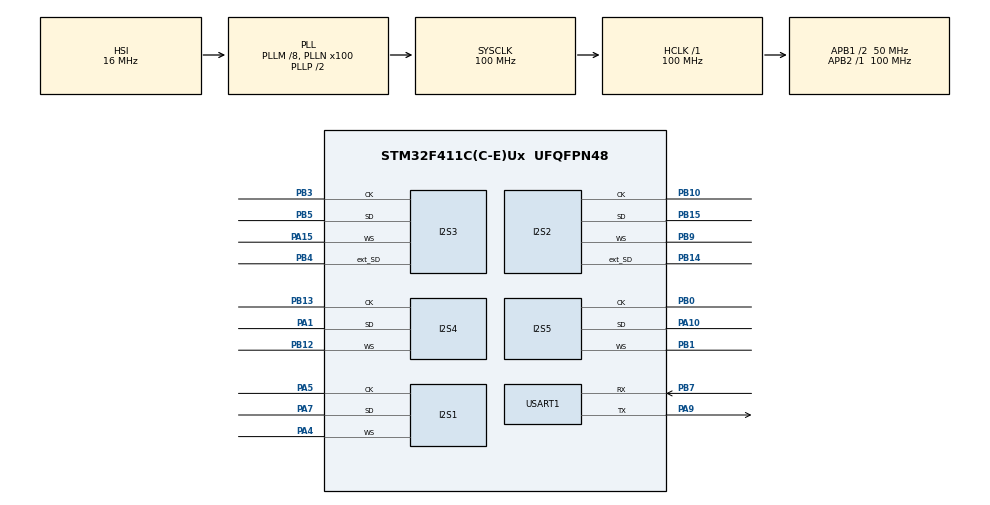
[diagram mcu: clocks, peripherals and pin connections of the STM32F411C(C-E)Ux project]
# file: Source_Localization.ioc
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Dma.Request0=SPI1_RX
Dma.SPI1_RX.0.Direction=DMA_PERIPH_TO_MEMORY
Dma.SPI1_RX.0.FIFOMode=DMA_FIFOMODE_DISABLE
Dma.SPI1_RX.0.Instance=DMA2_Stream0
Dma.SPI1_RX.0.MemDataAlignment=DMA_MDATAALIGN_WORD
Dma.SPI1_RX.0.MemInc=DMA_MINC_ENABLE
Dma.SPI1_RX.0.Mode=DMA_CIRCULAR
Dma.SPI1_RX.0.PeriphDataAlignment=DMA_PDATAALIGN_WORD
Dma.SPI1_RX.0.PeriphInc=DMA_PINC_DISABLE
Dma.SPI1_RX.0.Priority=DMA_PRIORITY_LOW
I2S1.DataFormat=I2S_DATAFORMAT_24B
I2S1.ErrorAudioFreq=-0.27 %
I2S1.FullDuplexMode=I2S_FULLDUPLEXMODE_DISABLE
I2S1.Instance=SPI$Index
I2S1.Mode=I2S_MODE_MASTER_RX
I2S1.RealAudioFreq=7.978 KHz
I2S1.VirtualMode=I2S_MODE_MASTER
I2S2.ErrorAudioFreq=0.0 %
I2S2.FullDuplexMode=I2S_FULLDUPLEXMODE_ENABLE
I2S2.Instance=SPI$Index
I2S2.RealAudioFreq=8.0 KHz
I2S2.VirtualMode=I2S_MODE_MASTER
I2S3.AudioFreq=I2S_AUDIOFREQ_8K
I2S3.ErrorAudioFreq=0.0 %
I2S3.FullDuplexMode=I2S_FULLDUPLEXMODE_ENABLE
I2S3.Instance=SPI$Index
I2S3.RealAudioFreq=8.0 KHz
I2S3.VirtualMode=I2S_MODE_MASTER
I2S4.ErrorAudioFreq=0.0 %
I2S4.FullDuplexMode=I2S_FULLDUPLEXMODE_DISABLE
I2S4.Instance=SPI$Index
I2S4.RealAudioFreq=8.0 KHz
I2S4.VirtualMode=I2S_MODE_MASTER
I2S5.ErrorAudioFreq=0.0 %
I2S5.FullDuplexMode=I2S_FULLDUPLEXMODE_DISABLE
I2S5.Instance=SPI$Index
I2S5.RealAudioFreq=8.0 KHz
I2S5.VirtualMode=I2S_MODE_MASTER
Mcu.Family=STM32F4
Mcu.Name=STM32F411C(C-E)Ux
Mcu.Package=UFQFPN48
NVIC.DMA2_Stream0_IRQn=true\:0\:0\:false\:false\:true\:false\:true\:true
NVIC.PriorityGroup=NVIC_PRIORITYGROUP_4
PA1.Mode=Half_Duplex_Master
PA1.Signal=I2S4_SD
PA10.Mode=Half_Duplex_Master
PA10.Signal=I2S5_SD
PA13.Mode=Serial_Wire
PA13.Signal=SYS_JTMS-SWDIO
PA14.Mode=Serial_Wire
PA14.Signal=SYS_JTCK-SWCLK
PA15.Mode=Full_Duplex_Master
PA15.Signal=I2S3_WS
PA4.Mode=Half_Duplex_Master
PA4.Signal=I2S1_WS
PA5.Mode=Half_Duplex_Master
PA5.Signal=I2S1_CK
PA7.Mode=Half_Duplex_Master
PA7.Signal=I2S1_SD
PA9.Mode=Asynchronous
PA9.Signal=USART1_TX
PB0.Mode=Half_Duplex_Master
PB0.Signal=I2S5_CK
PB1.Mode=Half_Duplex_Master
PB1.Signal=I2S5_WS
PB10.Mode=Full_Duplex_Master
PB10.Signal=I2S2_CK
PB12.Mode=Half_Duplex_Master
PB12.Signal=I2S4_WS
PB13.Mode=Half_Duplex_Master
PB13.Signal=I2S4_CK
PB14.Mode=Full_Duplex_Master
PB14.Signal=I2S2_ext_SD
PB15.Mode=Full_Duplex_Master
PB15.Signal=I2S2_SD
PB3.Mode=Full_Duplex_Master
PB3.Signal=I2S3_CK
PB4.Mode=Full_Duplex_Master
PB4.Signal=I2S3_ext_SD
PB5.Mode=Full_Duplex_Master
PB5.Signal=I2S3_SD
PB7.Mode=Asynchronous
PB7.Signal=USART1_RX
PB9.Mode=Full_Duplex_Master
PB9.Signal=I2S2_WS
PH0\ -\ OSC_IN.Mode=HSE-External-Oscillator
PH0\ -\ OSC_IN.Signal=RCC_OSC_IN
PH1\ -\ OSC_OUT.Mode=HSE-External-Oscillator
PH1\ -\ OSC_OUT.Signal=RCC_OSC_OUT
ProjectManager.HeapSize=0x200
ProjectManager.StackSize=0x400
ProjectManager.TargetToolchain=MDK-ARM V5.32
RCC.48MHZClocksFreq_Value=50000000
RCC.AHBFreq_Value=100000000
RCC.APB1CLKDivider=RCC_HCLK_DIV2
RCC.APB1Freq_Value=50000000
RCC.APB1TimFreq_Value=100000000
RCC.APB2Freq_Value=100000000
RCC.APB2TimFreq_Value=100000000
RCC.CortexFreq_Value=100000000
RCC.HCLKFreq_Value=100000000
RCC.HSE_VALUE=25000000
RCC.HSI_VALUE=16000000
RCC.LSE_VALUE=32768
RCC.PLLM=8
RCC.PLLN=100
RCC.SYSCLKFreq_VALUE=100000000
RCC.SYSCLKSource=RCC_SYSCLKSOURCE_PLLCLK
RCC.VCOOutputFreq_Value=200000000
STMicroelectronics.X-CUBE-ALGOBUILD.1.3.0.LibraryCcDSPOoLibraryJjDSPOoLibrary=true
USART1.VirtualMode=VM_ASYNC
VP_STMicroelectronics.X-CUBE-ALGOBUILD_VS_DSPOoLibraryJjLibrary_1.3.0_1.3.0.Mode=DSPOoLibraryJjLibrary
board=custom

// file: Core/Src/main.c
/* USER CODE BEGIN Header */
/**
  ******************************************************************************
  * @file           : main.c
  * @brief          : Main program body
  ******************************************************************************
  * @attention
  *
  * Copyright (c) 2023 STMicroelectronics.
  * All rights reserved.
  *
  * This software is licensed under terms that can be found in the LICENSE file
  * in the root directory of this software component.
  * If no LICENSE file comes with this software, it is provided AS-IS.
  *
  ******************************************************************************
  */
/* USER CODE END Header */
#include "main.h"
#include "dma.h"
#include "i2s.h"
#include "usart.h"
#include "gpio.h"

/* USER CODE BEGIN Includes */
#include "arm_math.h"
/* USER CODE END Includes */

void SystemClock_Config(void);
void PeriphCommonClock_Config(void);

int main(void)
{

  /* MCU Configuration--------------------------------------------------------*/

  /* Reset of all peripherals, Initializes the Flash interface and the Systick. */
  HAL_Init();

  /* Configure the system clock */
  SystemClock_Config();

/* Configure the peripherals common clocks */
  PeriphCommonClock_Config();

  /* Initialize all configured peripherals */
  MX_GPIO_Init();
  MX_DMA_Init();
  MX_I2S1_Init();
  MX_I2S2_Init();
  MX_I2S3_Init();
  MX_I2S4_Init();
  MX_I2S5_Init();
  MX_USART1_UART_Init();

  /* Infinite loop */
  /* USER CODE BEGIN WHILE */
	float data;
  while (1)
  {
		data = arm_sin_f32(3.1415926/6);
    /* USER CODE END WHILE */

  }
}

void SystemClock_Config(void)
{
  RCC_OscInitTypeDef RCC_OscInitStruct = {0};
  RCC_ClkInitTypeDef RCC_ClkInitStruct = {0};

  /** Configure the main internal regulator output voltage
  */
  __HAL_RCC_PWR_CLK_ENABLE();
  __HAL_PWR_VOLTAGESCALING_CONFIG(PWR_REGULATOR_VOLTAGE_SCALE1);

  /** Initializes the RCC Oscillators according to the specified parameters
  * in the RCC_OscInitTypeDef structure.
  */
  RCC_OscInitStruct.OscillatorType = RCC_OSCILLATORTYPE_HSI;
  RCC_OscInitStruct.HSIState = RCC_HSI_ON;
  RCC_OscInitStruct.HSICalibrationValue = RCC_HSICALIBRATION_DEFAULT;
  RCC_OscInitStruct.PLL.PLLState = RCC_PLL_ON;
  RCC_OscInitStruct.PLL.PLLSource = RCC_PLLSOURCE_HSI;
  RCC_OscInitStruct.PLL.PLLM = 8;
  RCC_OscInitStruct.PLL.PLLN = 100;
  RCC_OscInitStruct.PLL.PLLP = RCC_PLLP_DIV2;
  RCC_OscInitStruct.PLL.PLLQ = 4;
  if (HAL_RCC_OscConfig(&RCC_OscInitStruct) != HAL_OK)
  {
    Error_Handler();
  }

  /** Initializes the CPU, AHB and APB buses clocks
  */
  RCC_ClkInitStruct.ClockType = RCC_CLOCKTYPE_HCLK|RCC_CLOCKTYPE_SYSCLK
                              |RCC_CLOCKTYPE_PCLK1|RCC_CLOCKTYPE_PCLK2;
  RCC_ClkInitStruct.SYSCLKSource = RCC_SYSCLKSOURCE_PLLCLK;
  RCC_ClkInitStruct.AHBCLKDivider = RCC_SYSCLK_DIV1;
  RCC_ClkInitStruct.APB1CLKDivider = RCC_HCLK_DIV2;
  RCC_ClkInitStruct.APB2CLKDivider = RCC_HCLK_DIV1;

  if (HAL_RCC_ClockConfig(&RCC_ClkInitStruct, FLASH_LATENCY_3) != HAL_OK)
  {
    Error_Handler();
  }
}

void PeriphCommonClock_Config(void)
{
  RCC_PeriphCLKInitTypeDef PeriphClkInitStruct = {0};

  /** Initializes the peripherals clock
  */
  PeriphClkInitStruct.PeriphClockSelection = RCC_PERIPHCLK_I2S;
  PeriphClkInitStruct.PLLI2S.PLLI2SN = 192;
  PeriphClkInitStruct.PLLI2S.PLLI2SM = 16;
  PeriphClkInitStruct.PLLI2S.PLLI2SR = 2;
  if (HAL_RCCEx_PeriphCLKConfig(&PeriphClkInitStruct) != HAL_OK)
  {
    Error_Handler();
  }
}

void Error_Handler(void)
{
  __disable_irq();
  while (1)
  {
  }
}
